# XMC4500 register map
Vendor: Infineon; File version: 1.5.3 (Reference Manual v1.5)
CPU: CM4 r2p0, little endian, MPU, FPU, 6 interrupt priority bits
Registers are 32-bit, read-write, reset 0x0 unless marked. A register's access mark holds for its fields unless they carry their own. Offsets are from the block's base; [hi:lo] are bit positions; {n}, {i} and the like mark numbered series.

## CCU40 — Capture Compare Unit 4 - Unit 0
Base 0x4000C000
Same registers: CCU41 0x40010000, CCU42 0x40014000, CCU43 0x48004000
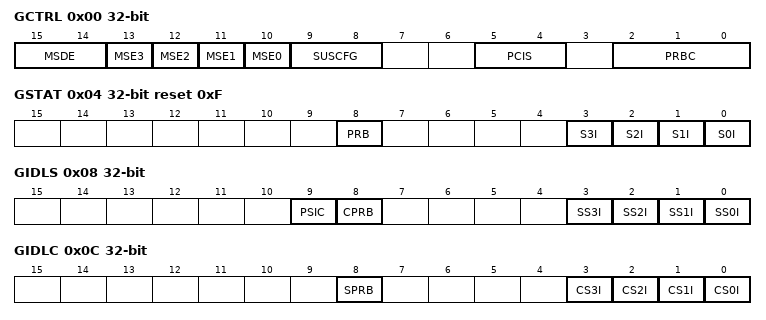
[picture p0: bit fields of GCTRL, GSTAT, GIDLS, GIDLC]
0x00 GCTRL — Global Control Register
  [15:14] MSDE — Multi Channel shadow transfer request configuration
    0=Only the shadow transfer for period and compare values is requested; 1=Shadow transfer for the compare, period and prescaler compare values is requested; 3=Shadow transfer for the compare, period, prescaler and dither compare values is requested
  [n+10] MSE{n} (n=0..3) — Slice {n} Multi Channel shadow transfer enable
    0=Shadow transfer can only be requested by SW; 1=Shadow transfer can be requested via SW and via the CCU4x.MCSS input
  [9:8] SUSCFG — Suspend Mode Configuration
    0=Suspend request ignored. The module never enters in suspend; 1=Stops all the running slices immediately. Safe stop is not applied.; 2=Stops the block immediately and clamps all the outputs to PASSIVE state. Safe stop is applied.; 3=Waits for the roll over of each slice to stop and clamp the slices outputs. Safe stop is applied.
  [5:4] PCIS — Prescaler Input Clock Selection
    0=Module clock; 1=CCU4x.ECLKA; 2=CCU4x.ECLKB; 3=CCU4x.ECLKC
  [2:0] PRBC — Prescaler Clear Configuration
    0=SW only; {v}=GSTATThe register contains the status of the prescaler and each timer slice (idle mode or running)..PRB and prescaler registers are cleared when the Run Bit of CC{v+39} is cleared (v=1..4)
0x04 GSTAT ro reset 0xF — Global Status Register
  [8] PRB — Prescaler Run Bit
    0=Prescaler is stopped; 1=Prescaler is running
  [n] S{n}I (n=0..3) — CC{n+40} IDLE status
    0=Running; 1=Idle
0x08 GIDLS wo — Global Idle Set
  [9] PSIC — Prescaler clear
  [8] CPRB — Prescaler Run Bit Clear
  [n] SS{n}I (n=0..3) — CC{n+40} IDLE mode set
0x0C GIDLC wo — Global Idle Clear
  [8] SPRB — Prescaler Run Bit Set
  [n] CS{n}I (n=0..3) — CC{n+40} IDLE mode clear
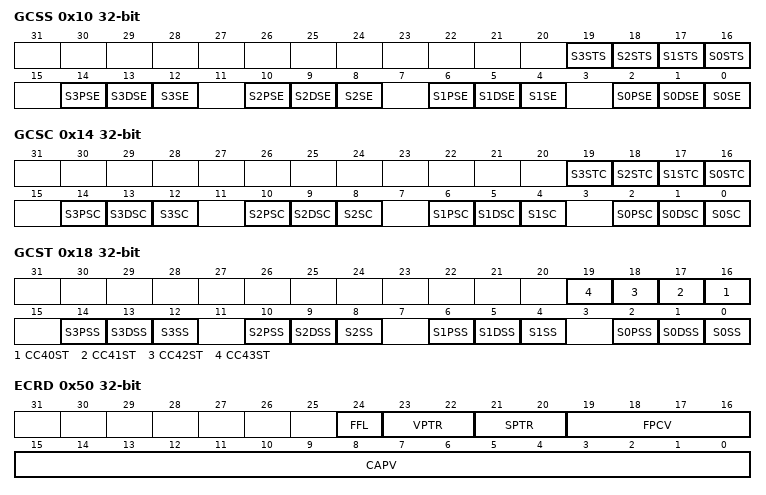
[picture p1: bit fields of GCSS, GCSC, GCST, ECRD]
0x10 GCSS wo — Global Channel Set
  [n+16] S{n}STS (n=0..3) — Slice {n} status bit set
  [4n+2] S{n}PSE (n=0..3) — Slice {n} Prescaler shadow transfer set enable
  [4n+1] S{n}DSE (n=0..3) — Slice {n} Dither shadow transfer set enable
  [4n] S{n}SE (n=0..3) — Slice {n} shadow transfer set enable
0x14 GCSC wo — Global Channel Clear
  [n+16] S{n}STC (n=0..3) — Slice {n} status bit clear
  [4n+2] S{n}PSC (n=0..3) — Slice {n} Prescaler shadow transfer clear
  [4n+1] S{n}DSC (n=0..3) — Slice {n} Dither shadow transfer clear
  [4n] S{n}SC (n=0..3) — Slice {n} shadow transfer clear
0x18 GCST ro — Global Channel Status
  [n-24] CC{n}ST (n=40..43) — Slice {n-40} status bit
  [4n+2] S{n}PSS (n=0..3) — Slice {n} Prescaler shadow transfer status
    0=Prescaler shadow transfer has not been requested; 1=Prescaler shadow transfer has been requested
  [4n+1] S{n}DSS (n=0..3) — Slice {n} Dither shadow transfer status
    0=Dither shadow transfer has not been requested; 1=Dither shadow transfer has been requested
  [4n] S{n}SS (n=0..3) — Slice {n} shadow transfer status
    0=Shadow transfer has not been requested; 1=Shadow transfer has been requested
0x50 ECRD ro read-has-side-effects — Extended Capture Mode Read
  [24] FFL — Full Flag
    0=No new value was captured into this register; 1=A new value has been captured into this register
  [23:22] VPTR — Capture register pointer
    {v}=Capture register {v} (v=0..3)
  [21:20] SPTR — Slice pointer
    {v}=CC{v+40} (v=0..3)
  [19:16] FPCV — Prescaler Capture value
  [15:0] CAPV — Timer Capture Value
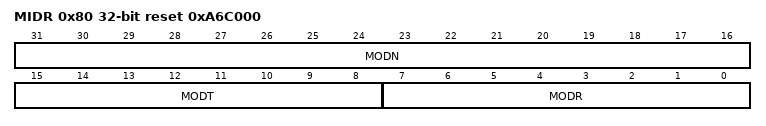
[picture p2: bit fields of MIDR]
0x80 MIDR ro reset 0xA6C000 (reset mask 0xFFFFFF00) — Module Identification
  [31:16] MODN — Module Number
  [15:8] MODT — Module Type
  [7:0] MODR — Module Revision
